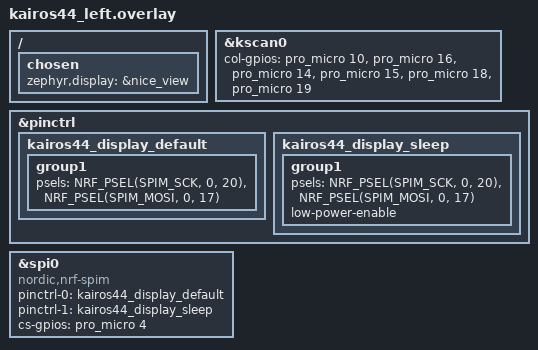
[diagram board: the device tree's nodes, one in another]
#include "kairos44.dtsi"
#include "kairos44-rgb.dtsi"

&kscan0 {
    col-gpios = <&pro_micro 10 GPIO_ACTIVE_HIGH>,
                <&pro_micro 16 GPIO_ACTIVE_HIGH>,
                <&pro_micro 14 GPIO_ACTIVE_HIGH>,
                <&pro_micro 15 GPIO_ACTIVE_HIGH>,
                <&pro_micro 18 GPIO_ACTIVE_HIGH>,
                <&pro_micro 19 GPIO_ACTIVE_HIGH>;
};

/ {
    chosen {
        zephyr,display = &nice_view;
    };
};

&pinctrl {
    kairos44_display_default: kairos44_display_default {
        group1 {
            psels = <NRF_PSEL(SPIM_SCK, 0, 20)>,
                    <NRF_PSEL(SPIM_MOSI, 0, 17)>;
        };
    };

    kairos44_display_sleep: kairos44_display_sleep {
        group1 {
            psels = <NRF_PSEL(SPIM_SCK, 0, 20)>,
                    <NRF_PSEL(SPIM_MOSI, 0, 17)>;
            low-power-enable;
        };
    };
};

nice_view_spi: &spi0 {
    compatible = "nordic,nrf-spim";
    status = "okay";
    pinctrl-0 = <&kairos44_display_default>;
    pinctrl-1 = <&kairos44_display_sleep>;
    pinctrl-names = "default", "sleep";
    cs-gpios = <&pro_micro 4 GPIO_ACTIVE_HIGH>;
};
